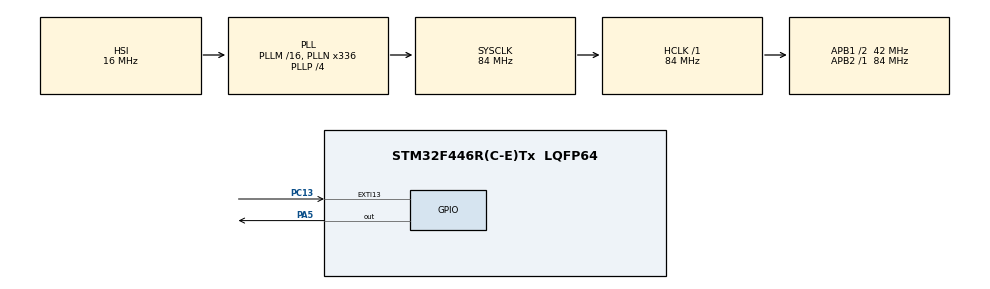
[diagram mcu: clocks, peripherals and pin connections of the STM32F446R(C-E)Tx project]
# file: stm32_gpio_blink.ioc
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FREERTOS.Queues01=heartbeatQueue,5,uint16_t,0,Dynamic,NULL,NULL
FREERTOS.Tasks01=heartbeatTask,8,128,StartHeartbeatTask,Default,NULL,Dynamic,NULL,NULL;MonitorTask,8,128,StartMonitorTask,Default,NULL,Dynamic,NULL,NULL
Mcu.Family=STM32F4
Mcu.Name=STM32F446R(C-E)Tx
Mcu.Package=LQFP64
NUCLEO-F446RE.BUTTON=1
NUCLEO-F446RE.LD1=true
NVIC.EXTI15_10_IRQn=true\:5\:0\:false\:false\:true\:true\:false\:true\:true
NVIC.PriorityGroup=NVIC_PRIORITYGROUP_4
NVIC.TIM2_IRQn=true\:5\:0\:false\:false\:true\:true\:true\:true\:true
NVIC.TIM6_DAC_IRQn=true\:15\:0\:false\:false\:true\:false\:false\:true\:true
NVIC.TimeBase=TIM6_DAC_IRQn
NVIC.TimeBaseIP=TIM6
PA13.GPIO_Label=TMS
PA13.Signal=SYS_JTMS-SWDIO
PA14.GPIO_Label=TCK
PA14.Signal=SYS_JTCK-SWCLK
PA2.GPIO_Label=USART_TX
PA2.Signal=USART2_TX
PA3.GPIO_Label=USART_RX
PA3.Signal=USART2_RX
PA5.Signal=GPIO_Output
PB3.GPIO_Label=SWO
PB3.Signal=SYS_JTDO-SWO
PC13.Signal=GPXTI13
PC14-OSC32_IN.Signal=RCC_OSC32_IN
PC15-OSC32_OUT.Signal=RCC_OSC32_OUT
PH0-OSC_IN.Signal=RCC_OSC_IN
PH1-OSC_OUT.Signal=RCC_OSC_OUT
ProjectManager.HeapSize=0x200
ProjectManager.StackSize=0x400
ProjectManager.TargetToolchain=CMake
RCC.AHBFreq_Value=84000000
RCC.APB1CLKDivider=RCC_HCLK_DIV2
RCC.APB1Freq_Value=42000000
RCC.APB1TimFreq_Value=84000000
RCC.APB2Freq_Value=84000000
RCC.APB2TimFreq_Value=84000000
RCC.CortexFreq_Value=84000000
RCC.FLatency-AdvancedSettings=FLASH_LATENCY_2
RCC.HCLKFreq_Value=84000000
RCC.HSE_VALUE=8000000
RCC.HSI_VALUE=16000000
RCC.LSE_VALUE=32768
RCC.PLLN=336
RCC.PLLP=RCC_PLLP_DIV4
RCC.SYSCLKFreq_VALUE=84000000
RCC.SYSCLKSource=RCC_SYSCLKSOURCE_PLLCLK
RCC.USBFreq_Value=168000000
RCC.VCOOutputFreq_Value=336000000
VP_FREERTOS_VS_CMSIS_V2.Mode=CMSIS_V2
VP_NUCLEO-F446RE_VS_BSP_COMMON.Mode=COMMON
VP_SYS_VS_tim6.Mode=TIM6
VP_TIM2_VS_ClockSourceINT.Mode=Internal
board=NUCLEO-F446RE

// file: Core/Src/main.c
/* USER CODE BEGIN Header */
/**
  ******************************************************************************
  * @file           : main.c
  * @brief          : Main program body
  ******************************************************************************
  * @attention
  *
  * Copyright (c) 2026 STMicroelectronics.
  * All rights reserved.
  *
  * This software is licensed under terms that can be found in the LICENSE file
  * in the root directory of this software component.
  * If no LICENSE file comes with this software, it is provided AS-IS.
  *
  ******************************************************************************
  */
/* USER CODE END Header */
#include "main.h"
#include "cmsis_os.h"
#include <stdbool.h>

/* USER CODE BEGIN PD */
#define HEARTBEAT_FLAG (1U << 0)
/* USER CODE END PD */

TIM_HandleTypeDef htim2;

/* Definitions for heartbeatTask */
osThreadId_t heartbeatTaskHandle;
const osThreadAttr_t heartbeatTask_attributes = {
  .name = "heartbeatTask",
  .stack_size = 128 * 4,
  .priority = (osPriority_t) osPriorityLow,
};
/* Definitions for MonitorTask */
osThreadId_t MonitorTaskHandle;
const osThreadAttr_t MonitorTask_attributes = {
  .name = "MonitorTask",
  .stack_size = 128 * 4,
  .priority = (osPriority_t) osPriorityLow,
};
/* Definitions for heartbeatQueue */
osMessageQueueId_t heartbeatQueueHandle;
const osMessageQueueAttr_t heartbeatQueue_attributes = {
  .name = "heartbeatQueue"
};
/* USER CODE BEGIN PV */
// volatile uint32_t last_heartbeat_count = 0U;
volatile uint32_t heartbeat_recd_count = 0U;
volatile uint32_t heartbeat_missed_count = 0U;
volatile uint32_t heartbeat_healthy = 0U;

/* USER CODE END PV */

void SystemClock_Config(void);
static void MX_GPIO_Init(void);
static void MX_TIM2_Init(void);
void StartHeartbeatTask(void *argument);
void StartMonitorTask(void *argument);

int main(void)
{

  /* MCU Configuration--------------------------------------------------------*/

  /* Reset of all peripherals, Initializes the Flash interface and the Systick. */
  HAL_Init();

  /* Configure the system clock */
  SystemClock_Config();

  /* Initialize all configured peripherals */
  MX_GPIO_Init();
  MX_TIM2_Init();
  /* USER CODE BEGIN 2 */
  if (HAL_TIM_Base_Start_IT(&htim2) != HAL_OK)
    {
        Error_Handler();
    }
  /* USER CODE END 2 */

  /* Init scheduler */
  osKernelInitialize();

  /* Create the queue(s) */
  /* creation of heartbeatQueue */
  heartbeatQueueHandle = osMessageQueueNew (5, sizeof(uint16_t), &heartbeatQueue_attributes);

  /* Create the thread(s) */
  /* creation of heartbeatTask */
  heartbeatTaskHandle = osThreadNew(StartHeartbeatTask, NULL, &heartbeatTask_attributes);

  /* creation of MonitorTask */
  MonitorTaskHandle = osThreadNew(StartMonitorTask, NULL, &MonitorTask_attributes);

  /* Initialize leds */
  BSP_LED_Init(LED2);

  /* Initialize USER push-button, will be used to trigger an interrupt each time it's pressed.*/
  BSP_PB_Init(BUTTON_USER, BUTTON_MODE_EXTI);

  /* Start scheduler */
  osKernelStart();

  /* We should never get here as control is now taken by the scheduler */

  /* Infinite loop */
  while (1)
  {

  }
}

void SystemClock_Config(void)
{
  RCC_OscInitTypeDef RCC_OscInitStruct = {0};
  RCC_ClkInitTypeDef RCC_ClkInitStruct = {0};

  /** Configure the main internal regulator output voltage
  */
  __HAL_RCC_PWR_CLK_ENABLE();
  __HAL_PWR_VOLTAGESCALING_CONFIG(PWR_REGULATOR_VOLTAGE_SCALE3);

  /** Initializes the RCC Oscillators according to the specified parameters
  * in the RCC_OscInitTypeDef structure.
  */
  RCC_OscInitStruct.OscillatorType = RCC_OSCILLATORTYPE_HSI;
  RCC_OscInitStruct.HSIState = RCC_HSI_ON;
  RCC_OscInitStruct.HSICalibrationValue = RCC_HSICALIBRATION_DEFAULT;
  RCC_OscInitStruct.PLL.PLLState = RCC_PLL_ON;
  RCC_OscInitStruct.PLL.PLLSource = RCC_PLLSOURCE_HSI;
  RCC_OscInitStruct.PLL.PLLM = 16;
  RCC_OscInitStruct.PLL.PLLN = 336;
  RCC_OscInitStruct.PLL.PLLP = RCC_PLLP_DIV4;
  RCC_OscInitStruct.PLL.PLLQ = 2;
  RCC_OscInitStruct.PLL.PLLR = 2;
  if (HAL_RCC_OscConfig(&RCC_OscInitStruct) != HAL_OK)
  {
    Error_Handler();
  }

  /** Initializes the CPU, AHB and APB buses clocks
  */
  RCC_ClkInitStruct.ClockType = RCC_CLOCKTYPE_HCLK|RCC_CLOCKTYPE_SYSCLK
                              |RCC_CLOCKTYPE_PCLK1|RCC_CLOCKTYPE_PCLK2;
  RCC_ClkInitStruct.SYSCLKSource = RCC_SYSCLKSOURCE_PLLCLK;
  RCC_ClkInitStruct.AHBCLKDivider = RCC_SYSCLK_DIV1;
  RCC_ClkInitStruct.APB1CLKDivider = RCC_HCLK_DIV2;
  RCC_ClkInitStruct.APB2CLKDivider = RCC_HCLK_DIV1;

  if (HAL_RCC_ClockConfig(&RCC_ClkInitStruct, FLASH_LATENCY_2) != HAL_OK)
  {
    Error_Handler();
  }
}

static void MX_TIM2_Init(void)
{

  TIM_ClockConfigTypeDef sClockSourceConfig = {0};
  TIM_MasterConfigTypeDef sMasterConfig = {0};

  htim2.Instance = TIM2;
  htim2.Init.Prescaler = 0;
  htim2.Init.CounterMode = TIM_COUNTERMODE_UP;
  htim2.Init.Period = 4294967295;
  htim2.Init.ClockDivision = TIM_CLOCKDIVISION_DIV1;
  htim2.Init.AutoReloadPreload = TIM_AUTORELOAD_PRELOAD_DISABLE;
  if (HAL_TIM_Base_Init(&htim2) != HAL_OK)
  {
    Error_Handler();
  }
  sClockSourceConfig.ClockSource = TIM_CLOCKSOURCE_INTERNAL;
  if (HAL_TIM_ConfigClockSource(&htim2, &sClockSourceConfig) != HAL_OK)
  {
    Error_Handler();
  }
  sMasterConfig.MasterOutputTrigger = TIM_TRGO_RESET;
  sMasterConfig.MasterSlaveMode = TIM_MASTERSLAVEMODE_DISABLE;
  if (HAL_TIMEx_MasterConfigSynchronization(&htim2, &sMasterConfig) != HAL_OK)
  {
    Error_Handler();
  }

}

static void MX_GPIO_Init(void)
{
  GPIO_InitTypeDef GPIO_InitStruct = {0};

  /* GPIO Ports Clock Enable */
  __HAL_RCC_GPIOC_CLK_ENABLE();
  __HAL_RCC_GPIOH_CLK_ENABLE();
  __HAL_RCC_GPIOA_CLK_ENABLE();
  __HAL_RCC_GPIOB_CLK_ENABLE();

  /*Configure GPIO pins : USART_TX_Pin USART_RX_Pin */
  GPIO_InitStruct.Pin = USART_TX_Pin|USART_RX_Pin;
  GPIO_InitStruct.Mode = GPIO_MODE_AF_PP;
  GPIO_InitStruct.Pull = GPIO_NOPULL;
  GPIO_InitStruct.Speed = GPIO_SPEED_FREQ_VERY_HIGH;
  GPIO_InitStruct.Alternate = GPIO_AF7_USART2;
  HAL_GPIO_Init(GPIOA, &GPIO_InitStruct);

}

/* USER CODE BEGIN 4 */
// void HAL_TIM_PeriodElapsedCallback(TIM_HandleTypeDef *htim) {
  // if(htim2.Instance == TIM2) {
  //   HAL_GPIO_TogglePin(LED2_GPIO_PORT, LED2_PIN);
  // }
// }
/* USER CODE END 4 */

/* USER CODE BEGIN Header_StartHeartbeatTask */
/**
  * @brief  Function implementing the heartbeatTask thread.
  * @param  argument: Not used
  * @retval None
  */

volatile uint32_t queue_send_fails = 0U;
/* USER CODE END Header_StartHeartbeatTask */
void StartHeartbeatTask(void *argument)
{
  /* USER CODE BEGIN 5 */

  for(;;)
  {
    HAL_GPIO_TogglePin(LED2_GPIO_PORT,LED2_PIN);

    osThreadFlagsSet(MonitorTaskHandle,HEARTBEAT_FLAG);

    osDelay(3000U);

  }
  /* USER CODE END 5 */
}

/* USER CODE BEGIN Header_StartMonitorTask */
/**
* @brief Function implementing the MonitorTask thread.
* @param argument: Not used
* @retval None
*/
 volatile uint32_t heartbeat_notifications = 0U;
/* USER CODE END Header_StartMonitorTask */
void StartMonitorTask(void *argument)
{
  /* USER CODE BEGIN StartMonitorTask */
  volatile uint32_t monitor_count = 0U;

  /* Infinite loop */
  for(;;)
  {

    uint32_t flags = osThreadFlagsWait(HEARTBEAT_FLAG,osFlagsWaitAny,1000U);

    if((flags & osFlagsError) != 0U) {
      heartbeat_missed_count++;
      heartbeat_healthy = false;
    }

    else if((flags & HEARTBEAT_FLAG) != 0U){
      heartbeat_recd_count++;
      heartbeat_healthy = true;
    }

  }
  /* USER CODE END StartMonitorTask */
}

void HAL_TIM_PeriodElapsedCallback(TIM_HandleTypeDef *htim)
{
  if (htim->Instance == TIM6)
  {
    HAL_IncTick();
  }
}

void Error_Handler(void)
{
  __disable_irq();
  while (1)
  {
  }
}
